# MSP430FR5739 register map
File version: 1.1
CPU: msp430
Registers are 16-bit, access not given, reset 0x0 unless marked. A register's access mark holds for its fields unless they carry their own. Offsets are from the block's base; [hi:lo] are bit positions; {n}, {i} and the like mark numbered series.

## Port_B
Base 0x00000000
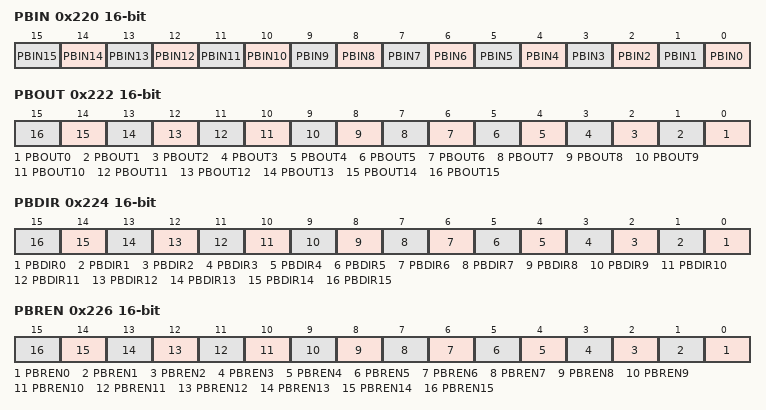
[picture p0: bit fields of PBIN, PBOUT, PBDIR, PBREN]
0x220 PBIN — Port B Input
  [n] PBIN{n} (n=0..15) — [{n}:{n}] PBIN{n}
0x222 PBOUT — Port B Output
  [n] PBOUT{n} (n=0..15) — [{n}:{n}] PBOUT{n}
0x224 PBDIR — Port B Direction
  [n] PBDIR{n} (n=0..15) — [{n}:{n}] PBDIR{n}
0x226 PBREN — Port B Resistor Enable
  [n] PBREN{n} (n=0..15) — [{n}:{n}] PBREN{n}
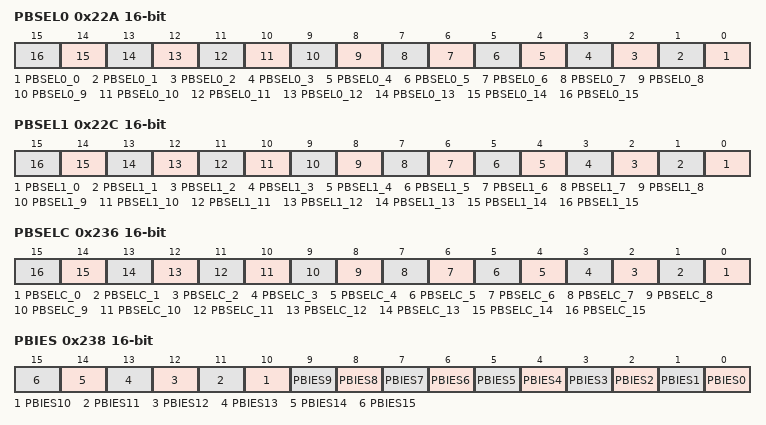
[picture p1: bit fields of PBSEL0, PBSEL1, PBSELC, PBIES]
0x22A PBSEL0 — Port B Selection 0
  [n] PBSEL0_{n} (n=0..15) — [{n}:{n}] PBSEL0_{n}
0x22C PBSEL1 — Port B Selection 1
  [n] PBSEL1_{n} (n=0..15) — [{n}:{n}] PBSEL1_{n}
0x236 PBSELC — Port B Complement Selection
  [n] PBSELC_{n} (n=0..15) — [{n}:{n}] PBSELC_{n}
0x238 PBIES — Port B Interrupt Edge Select
  [n] PBIES{n} (n=0..15) — [{n}:{n}] PBIES{n}
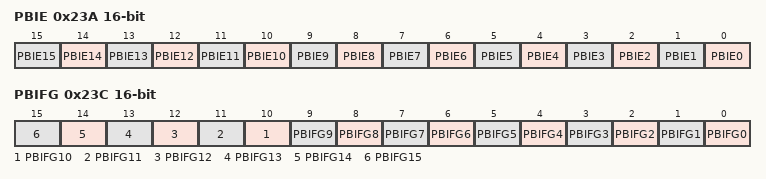
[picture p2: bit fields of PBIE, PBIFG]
0x23A PBIE — Port B Interrupt Enable
  [n] PBIE{n} (n=0..15) — [{n}:{n}] PBIE{n}
0x23C PBIFG — Port B Interrupt Flag
  [n] PBIFG{n} (n=0..15) — [{n}:{n}] PBIFG{n}

## Port_3_4
Base 0x00000000
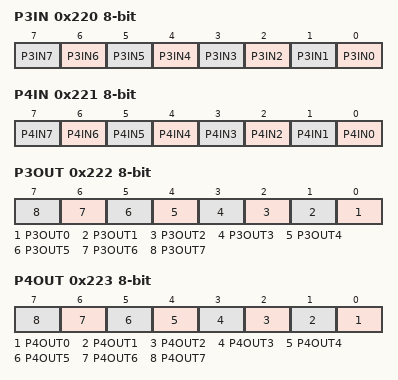
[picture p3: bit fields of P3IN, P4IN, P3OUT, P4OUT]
0x220 P3IN 8-bit — Port 3 Input
  [n] P3IN{n} (n=0..7) — [{n}:{n}] P3IN{n}
0x221 P4IN 8-bit — Port 4 Input
  [n] P4IN{n} (n=0..7) — [{n}:{n}] P4IN{n}
0x222 P3OUT 8-bit — Port 3 Output
  [n] P3OUT{n} (n=0..7) — [{n}:{n}] P3OUT{n}
0x223 P4OUT 8-bit — Port 4 Output
  [n] P4OUT{n} (n=0..7) — [{n}:{n}] P4OUT{n}
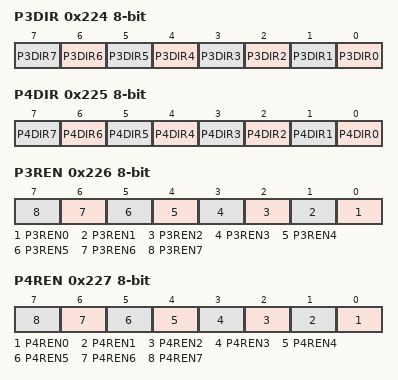
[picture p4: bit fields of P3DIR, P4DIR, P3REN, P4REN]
0x224 P3DIR 8-bit — Port 3 Direction
  [n] P3DIR{n} (n=0..7) — [{n}:{n}] P3DIR{n}
0x225 P4DIR 8-bit — Port 4 Direction
  [n] P4DIR{n} (n=0..7) — [{n}:{n}] P4DIR{n}
0x226 P3REN 8-bit — Port 3 Resistor Enable
  [n] P3REN{n} (n=0..7) — [{n}:{n}] P3REN{n}
0x227 P4REN 8-bit — Port 4 Resistor Enable
  [n] P4REN{n} (n=0..7) — [{n}:{n}] P4REN{n}
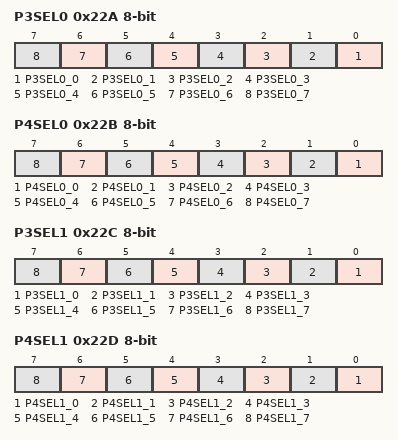
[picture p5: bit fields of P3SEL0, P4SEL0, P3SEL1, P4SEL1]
0x22A P3SEL0 8-bit — Port 3 Selection 0
  [n] P3SEL0_{n} (n=0..7) — [{n}:{n}] P3SEL0_{n}
0x22B P4SEL0 8-bit — Port 4 Selection 0
  [n] P4SEL0_{n} (n=0..7) — [{n}:{n}] P4SEL0_{n}
0x22C P3SEL1 8-bit — Port 3 Selection 1
  [n] P3SEL1_{n} (n=0..7) — [{n}:{n}] P3SEL1_{n}
0x22D P4SEL1 8-bit — Port 4 Selection 1
  [n] P4SEL1_{n} (n=0..7) — [{n}:{n}] P4SEL1_{n}
0x22E P3IV — Port 3 Interrupt Vector Word
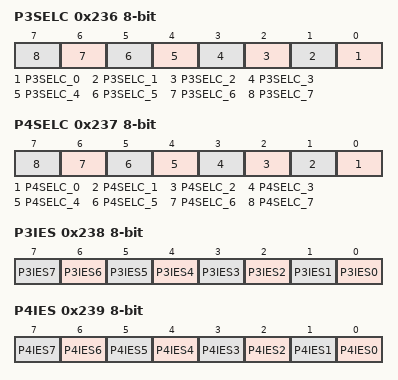
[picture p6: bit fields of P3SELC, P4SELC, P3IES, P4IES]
0x236 P3SELC 8-bit — Port 3 Complement Selection
  [n] P3SELC_{n} (n=0..7) — [{n}:{n}] P3SELC_{n}
0x237 P4SELC 8-bit — Port 4 Complement Selection
  [n] P4SELC_{n} (n=0..7) — [{n}:{n}] P4SELC_{n}
0x238 P3IES 8-bit — Port 3 Interrupt Edge Select
  [n] P3IES{n} (n=0..7) — [{n}:{n}] P3IES{n}
0x239 P4IES 8-bit — Port 4 Interrupt Edge Select
  [n] P4IES{n} (n=0..7) — [{n}:{n}] P4IES{n}
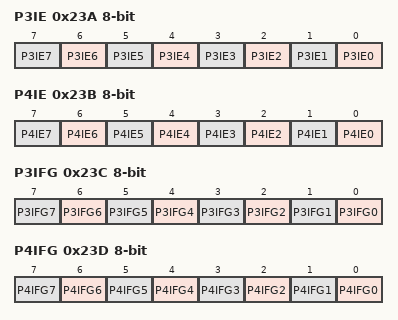
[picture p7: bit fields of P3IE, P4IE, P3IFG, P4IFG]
0x23A P3IE 8-bit — Port 3 Interrupt Enable
  [n] P3IE{n} (n=0..7) — [{n}:{n}] P3IE{n}
0x23B P4IE 8-bit — Port 4 Interrupt Enable
  [n] P4IE{n} (n=0..7) — [{n}:{n}] P4IE{n}
0x23C P3IFG 8-bit — Port 3 Interrupt Flag
  [n] P3IFG{n} (n=0..7) — [{n}:{n}] P3IFG{n}
0x23D P4IFG 8-bit — Port 4 Interrupt Flag
  [n] P4IFG{n} (n=0..7) — [{n}:{n}] P4IFG{n}
0x23E P4IV — Port 4 Interrupt Vector Word

## Port_J
Base 0x00000000
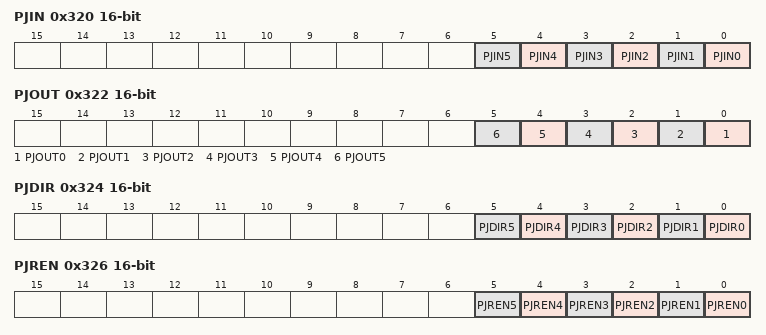
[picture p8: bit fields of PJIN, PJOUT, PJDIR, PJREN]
0x320 PJIN — Port J Input
  [n] PJIN{n} (n=0..5) — [{n}:{n}] PJIN{n}
0x322 PJOUT — Port J Output
  [n] PJOUT{n} (n=0..5) — [{n}:{n}] PJOUT{n}
0x324 PJDIR — Port J Direction
  [n] PJDIR{n} (n=0..5) — [{n}:{n}] PJDIR{n}
0x326 PJREN — Port J Resistor Enable
  [n] PJREN{n} (n=0..5) — [{n}:{n}] PJREN{n}
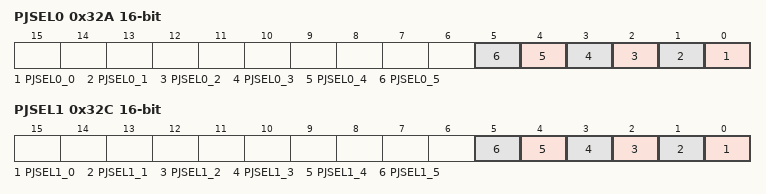
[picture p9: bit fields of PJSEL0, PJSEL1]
0x32A PJSEL0 — Port J Selection 0
  [n] PJSEL0_{n} (n=0..5) — [{n}:{n}] PJSEL0_{n}
0x32C PJSEL1 — Port J Selection 1
  [n] PJSEL1_{n} (n=0..5) — [{n}:{n}] PJSEL1_{n}
0x336 PJSELC — Port J Complement Selection

## Shared_Reference
Base 0x00000000
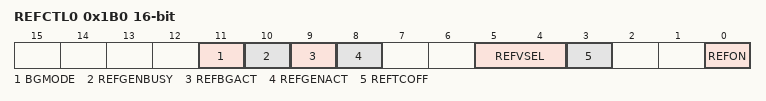
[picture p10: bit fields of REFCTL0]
0x1B0 REFCTL0 — REF Shared Reference control register 0
  [11] BGMODE — [11:11] REF Bandgap mode
  [10] REFGENBUSY — [10:10] REF Reference generator busy
  [9] REFBGACT — [9:9] REF Reference bandgap active
  [8] REFGENACT — [8:8] REF Reference generator active
  [5:4] REFVSEL — [5:4] REF Reference Voltage Level Select Bit:0
    0=REF Reference Voltage Level Select 1.5V; 1=REF Reference Voltage Level Select 2.0V; 2=REF Reference Voltage Level Select 2.5V; 3=REF Reference Voltage Level Select 2.5V
  [3] REFTCOFF — [3:3] REF Temp.Sensor off
  [0] REFON — [0:0] REF Reference On
